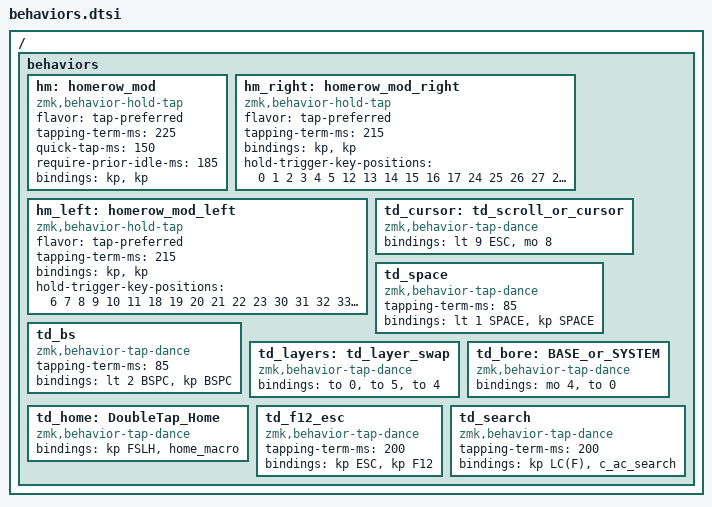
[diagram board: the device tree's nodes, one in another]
/ {
    behaviors {
        hm: homerow_mod {
            compatible = "zmk,behavior-hold-tap";
            #binding-cells = <2>;
            flavor = "tap-preferred";
            tapping-term-ms = <225>; // triggers the hold behavior when the tapping-term-ms has expired
            quick-tap-ms = <150>; // If you press a tapped hold-tap again within quick-tap-ms milliseconds of the first press, it will always trigger the tap behavior.
            require-prior-idle-ms = <185>; // like quick-tap-ms however it will apply for any non-modifier key pressed before it
            bindings = <&kp>, <&kp>;  // hold, tap
        };

        hm_right: homerow_mod_right {
            compatible = "zmk,behavior-hold-tap";
            #binding-cells = <2>;
            flavor = "tap-preferred";
            tapping-term-ms = <215>;
            // quick-tap-ms = <200>;
            // require-prior-idle-ms = <150>;
            bindings = <&kp>, <&kp>;
            hold-trigger-key-positions = <0 1 2 3 4 5 12 13 14 15 16 17 24 25 26 27 28 29 36 37 38>;
        };

        hm_left: homerow_mod_left {
            compatible = "zmk,behavior-hold-tap";
            #binding-cells = <2>;
            flavor = "tap-preferred";
            tapping-term-ms = <215>;
            // quick-tap-ms = <200>;
            // require-prior-idle-ms = <150>;
            bindings = <&kp>, <&kp>;
            hold-trigger-key-positions = <6 7 8 9 10 11 18 19 20 21 22 23 30 31 32 33 34 35 39 40>;
        };

        td_cursor: td_scroll_or_cursor {
            compatible = "zmk,behavior-tap-dance";
            #binding-cells = <0>;
            bindings = <&lt 9 ESC>, <&mo 8>; // hold, tap, double_tap
        };

        td_space: td_space {
            compatible = "zmk,behavior-tap-dance";
            #binding-cells = <0>;
            tapping-term-ms = <85>;
            bindings = <&lt 1 SPACE>, <&kp SPACE>; // hold, tap, double_tap
        };

        td_bs: td_bs {
            compatible = "zmk,behavior-tap-dance";
            #binding-cells = <0>;
            tapping-term-ms = <85>;
            bindings = <&lt 2 BSPC>, <&kp BSPC>; // hold, tap, double_tap
        };

        td_layers: td_layer_swap {
            compatible = "zmk,behavior-tap-dance";
            #binding-cells = <0>;
            bindings = <&to 0>, <&to 5>, <&to 4>; // tap, double_tap, tripple_tap
        };

        td_bore: BASE_or_SYSTEM {
            compatible = "zmk,behavior-tap-dance";
            #binding-cells = <0>;
            bindings = <&mo 4>, <&to 0>;
        };

        td_home: DoubleTap_Home {
            compatible = "zmk,behavior-tap-dance";
            #binding-cells = <0>;
            bindings = <&kp FSLH>, <&home_macro>;
        };

        td_f12_esc: td_f12_esc {
            compatible = "zmk,behavior-tap-dance";
            #binding-cells = <0>;
            tapping-term-ms = <200>; // Adjust this timing as needed
            bindings = <&kp ESC>, <&kp F12>; // Single tap = ESC double tap = F12,
        };

        td_search: td_search {
            compatible = "zmk,behavior-tap-dance";
            #binding-cells = <0>;
            tapping-term-ms = <200>;
            bindings = <&kp LC(F)>, <&c_ac_search>;
        };
    };
};
